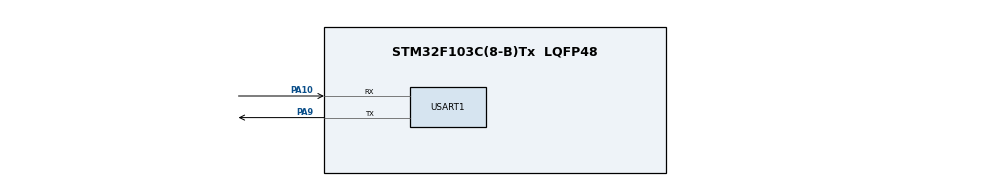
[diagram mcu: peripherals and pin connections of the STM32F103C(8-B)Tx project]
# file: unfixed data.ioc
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Mcu.Family=STM32F1
Mcu.Name=STM32F103C(8-B)Tx
Mcu.Package=LQFP48
NVIC.PriorityGroup=NVIC_PRIORITYGROUP_4
NVIC.TIM2_IRQn=true\:0\:0\:false\:false\:true\:true\:true\:true
NVIC.USART1_IRQn=true\:0\:0\:false\:false\:true\:true\:true\:true
PA10.Mode=Asynchronous
PA10.Signal=USART1_RX
PA13.Mode=Serial_Wire
PA13.Signal=SYS_JTMS-SWDIO
PA14.Mode=Serial_Wire
PA14.Signal=SYS_JTCK-SWCLK
PA9.Mode=Asynchronous
PA9.Signal=USART1_TX
ProjectManager.HeapSize=0x200
ProjectManager.StackSize=0x400
ProjectManager.TargetToolchain=MDK-ARM V5.32
RCC.APB1Freq_Value=8000000
RCC.APB2Freq_Value=8000000
TIM2.AutoReloadPreload=TIM_AUTORELOAD_PRELOAD_ENABLE
TIM2.Period=1000-1
TIM2.Prescaler=8000-1
USART1.VirtualMode=VM_ASYNC
VP_TIM2_VS_ClockSourceINT.Mode=Internal
board=custom

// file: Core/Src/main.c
/* USER CODE BEGIN Header */
/**
  ******************************************************************************
  * @file           : main.c
  * @brief          : Main program body
  ******************************************************************************
  * @attention
  *
  * Copyright (c) 2025 STMicroelectronics.
  * All rights reserved.
  *
  * This software is licensed under terms that can be found in the LICENSE file
  * in the root directory of this software component.
  * If no LICENSE file comes with this software, it is provided AS-IS.
  *
  ******************************************************************************
  */
/* USER CODE END Header */
#include "main.h"

/* USER CODE BEGIN Includes */
#include <stdio.h>
#include <string.h>
/* USER CODE END Includes */

/* USER CODE BEGIN PD */
struct id_data
{
	uint8_t id;
	uint8_t num;
	uint8_t dist1;
	uint8_t dist2;
	uint8_t dist3;
	uint8_t dist4;
};
/* USER CODE END PD */

TIM_HandleTypeDef htim2;

UART_HandleTypeDef huart1;

/* USER CODE BEGIN PV */
static uint8_t rev_it_buf[128] = {0};
static char send_it_buf[64] = {0};
static uint8_t cnt = 0; //count
static uint8_t temp_data;
static uint8_t send_len;
struct id_data id1;
/* USER CODE END PV */

void SystemClock_Config(void);
static void MX_GPIO_Init(void);
static void MX_TIM2_Init(void);
static void MX_USART1_UART_Init(void);

int main(void)
{

  /* MCU Configuration--------------------------------------------------------*/

  /* Reset of all peripherals, Initializes the Flash interface and the Systick. */
  HAL_Init();

  /* Configure the system clock */
  SystemClock_Config();

  /* Initialize all configured peripherals */
  MX_GPIO_Init();
  MX_TIM2_Init();
  MX_USART1_UART_Init();
  /* USER CODE BEGIN 2 */
HAL_UART_Receive_IT(&huart1,&temp_data,1);
  /* USER CODE END 2 */

  /* Infinite loop */
  while (1)
  {

  }
}

void SystemClock_Config(void)
{
  RCC_OscInitTypeDef RCC_OscInitStruct = {0};
  RCC_ClkInitTypeDef RCC_ClkInitStruct = {0};

  /** Initializes the RCC Oscillators according to the specified parameters
  * in the RCC_OscInitTypeDef structure.
  */
  RCC_OscInitStruct.OscillatorType = RCC_OSCILLATORTYPE_HSI;
  RCC_OscInitStruct.HSIState = RCC_HSI_ON;
  RCC_OscInitStruct.HSICalibrationValue = RCC_HSICALIBRATION_DEFAULT;
  RCC_OscInitStruct.PLL.PLLState = RCC_PLL_NONE;
  if (HAL_RCC_OscConfig(&RCC_OscInitStruct) != HAL_OK)
  {
    Error_Handler();
  }

  /** Initializes the CPU, AHB and APB buses clocks
  */
  RCC_ClkInitStruct.ClockType = RCC_CLOCKTYPE_HCLK|RCC_CLOCKTYPE_SYSCLK
                              |RCC_CLOCKTYPE_PCLK1|RCC_CLOCKTYPE_PCLK2;
  RCC_ClkInitStruct.SYSCLKSource = RCC_SYSCLKSOURCE_HSI;
  RCC_ClkInitStruct.AHBCLKDivider = RCC_SYSCLK_DIV1;
  RCC_ClkInitStruct.APB1CLKDivider = RCC_HCLK_DIV1;
  RCC_ClkInitStruct.APB2CLKDivider = RCC_HCLK_DIV1;

  if (HAL_RCC_ClockConfig(&RCC_ClkInitStruct, FLASH_LATENCY_0) != HAL_OK)
  {
    Error_Handler();
  }
}

static void MX_TIM2_Init(void)
{

  TIM_ClockConfigTypeDef sClockSourceConfig = {0};
  TIM_MasterConfigTypeDef sMasterConfig = {0};

  htim2.Instance = TIM2;
  htim2.Init.Prescaler = 8000-1;
  htim2.Init.CounterMode = TIM_COUNTERMODE_UP;
  htim2.Init.Period = 1000-1;
  htim2.Init.ClockDivision = TIM_CLOCKDIVISION_DIV1;
  htim2.Init.AutoReloadPreload = TIM_AUTORELOAD_PRELOAD_ENABLE;
  if (HAL_TIM_Base_Init(&htim2) != HAL_OK)
  {
    Error_Handler();
  }
  sClockSourceConfig.ClockSource = TIM_CLOCKSOURCE_INTERNAL;
  if (HAL_TIM_ConfigClockSource(&htim2, &sClockSourceConfig) != HAL_OK)
  {
    Error_Handler();
  }
  sMasterConfig.MasterOutputTrigger = TIM_TRGO_RESET;
  sMasterConfig.MasterSlaveMode = TIM_MASTERSLAVEMODE_DISABLE;
  if (HAL_TIMEx_MasterConfigSynchronization(&htim2, &sMasterConfig) != HAL_OK)
  {
    Error_Handler();
  }

}

static void MX_USART1_UART_Init(void)
{

  huart1.Instance = USART1;
  huart1.Init.BaudRate = 115200;
  huart1.Init.WordLength = UART_WORDLENGTH_8B;
  huart1.Init.StopBits = UART_STOPBITS_1;
  huart1.Init.Parity = UART_PARITY_NONE;
  huart1.Init.Mode = UART_MODE_TX_RX;
  huart1.Init.HwFlowCtl = UART_HWCONTROL_NONE;
  huart1.Init.OverSampling = UART_OVERSAMPLING_16;
  if (HAL_UART_Init(&huart1) != HAL_OK)
  {
    Error_Handler();
  }

}

static void MX_GPIO_Init(void)
{

  /* GPIO Ports Clock Enable */
  __HAL_RCC_GPIOA_CLK_ENABLE();

}

/* USER CODE BEGIN 4 */
void HAL_UART_RxCpltCallback(UART_HandleTypeDef *huart)
{
    if (huart == &huart1)
    {
        HAL_TIM_Base_Stop_IT(&htim2);

        rev_it_buf[cnt] = temp_data;
        cnt++;
        __HAL_TIM_SET_COUNTER(&htim2, 0);
        HAL_TIM_Base_Start_IT(&htim2);

        HAL_UART_Receive_IT(&huart1, &temp_data, 1);
    }
}

void HAL_TIM_PeriodElapsedCallback(TIM_HandleTypeDef *htim)
{
    if (htim == &htim2)
    {
        HAL_TIM_Base_Stop_IT(&htim2);

        if (cnt >= 4 && rev_it_buf[0] == 0xCC && rev_it_buf[1] == 0xDD)
        {
            id1.id = rev_it_buf[2];
            id1.num = rev_it_buf[3];
            id1.dist1 = 0;
            id1.dist2 = 0;
            id1.dist3 = 0;
            id1.dist4 = 0;
            if (cnt >= 5) id1.dist1 = rev_it_buf[4];
            if (cnt >= 6) id1.dist2 = rev_it_buf[5];
            if (cnt >= 7) id1.dist3 = rev_it_buf[6];
            if (cnt >= 8) id1.dist4 = rev_it_buf[7];

            send_len = sprintf(send_it_buf, "ID:%d 个数:%d 距离:%d %d %d %d\r\n",
                             id1.id, id1.num, id1.dist1, id1.dist2, id1.dist3, id1.dist4);

            HAL_UART_Transmit(&huart1, (uint8_t *)send_it_buf, send_len, 1000);
        }
        else
        {
            char err[] = "ERROR\r\n";
            HAL_UART_Transmit(&huart1, (uint8_t *)err, sizeof(err)-1, 1000);
        }
        memset(rev_it_buf, 0, sizeof(rev_it_buf));
        cnt = 0;
        HAL_UART_Receive_IT(&huart1, &temp_data, 1);
    }
}

/* USER CODE END 4 */

void Error_Handler(void)
{
  __disable_irq();
  while (1)
  {
  }
}
